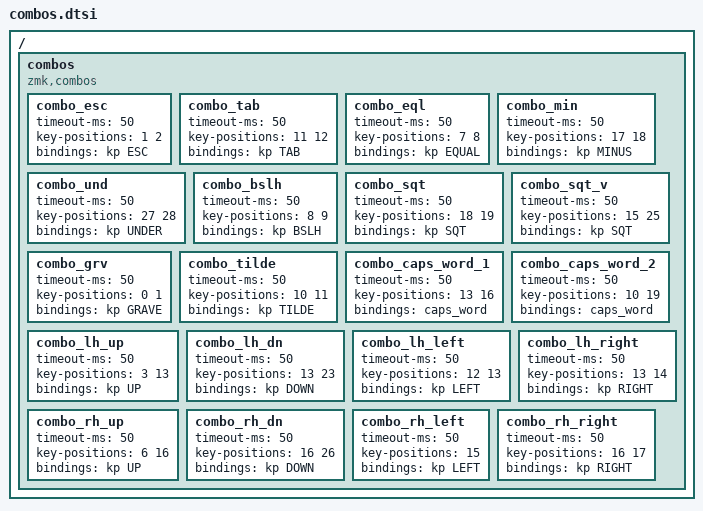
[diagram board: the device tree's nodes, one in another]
/ {
    combos {
        compatible = "zmk,combos";

        combo_esc {
            timeout-ms = <50>;
            key-positions = <1 2>;
            bindings = <&kp ESC>;
        };

        combo_tab {
            timeout-ms = <50>;
            key-positions = <11 12>;
            bindings = <&kp TAB>;
        };

        combo_eql {
            timeout-ms = <50>;
            key-positions = <7 8>;
            bindings = <&kp EQUAL>;
        };

        combo_min {
            timeout-ms = <50>;
            key-positions = <17 18>;
            bindings = <&kp MINUS>;
        };
    
        combo_und {
            timeout-ms = <50>;
            key-positions = <27 28>;
            bindings = <&kp UNDER>;
        };

        combo_bslh {
            timeout-ms = <50>;
            key-positions = <8 9>;
            bindings = <&kp BSLH>;
        };

        combo_sqt {
            timeout-ms = <50>;
            key-positions = <18 19>;
            bindings = <&kp SQT>;
        };

        combo_sqt_v {
            timeout-ms = <50>;
            key-positions = <15 25>;
            bindings = <&kp SQT>;
        };

        combo_grv {
            timeout-ms = <50>;
            key-positions = <0 1>;
            bindings = <&kp GRAVE>;
        };

        combo_tilde {
            timeout-ms = <50>;
            key-positions = <10 11>;
            bindings = <&kp TILDE>;
        };

        combo_caps_word_1 {
            timeout-ms = <50>;
            key-positions = <13 16>;
            bindings = <&caps_word>;
        };

        combo_caps_word_2 {
            timeout-ms = <50>;
            key-positions = <10 19>;
            bindings = <&caps_word>;
        };

        combo_lh_up {
            timeout-ms = <50>;
            key-positions = <3 13>;
            bindings = <&kp UP>;
        };

        combo_lh_dn {
            timeout-ms = <50>;
            key-positions = <13 23>;
            bindings = <&kp DOWN>;
        };

        combo_lh_left {
            timeout-ms = <50>;
            key-positions = <12 13>;
            bindings = <&kp LEFT>;
        };

        combo_lh_right {
            timeout-ms = <50>;
            key-positions = <13 14>;
            bindings = <&kp RIGHT>;
        };

        combo_rh_up {
            timeout-ms = <50>;
            key-positions = <6 16>;
            bindings = <&kp UP>;
        };

        combo_rh_dn {
            timeout-ms = <50>;
            key-positions = <16 26>;
            bindings = <&kp DOWN>;
        };

        combo_rh_left {
            timeout-ms = <50>;
            key-positions = <15 16;
            bindings = <&kp LEFT>;
        };

        combo_rh_right {
            timeout-ms = <50>;
            key-positions = <16 17>;
            bindings = <&kp RIGHT>;
        };
    };
};
